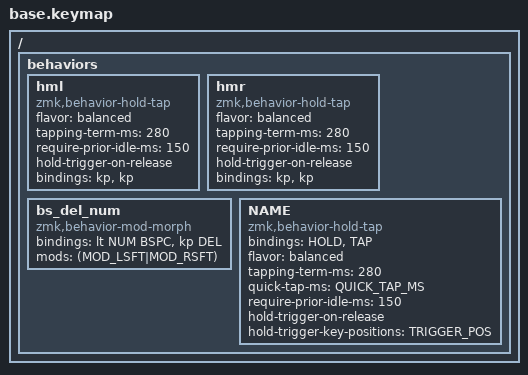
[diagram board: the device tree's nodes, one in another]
// https://github.com/urob/zmk-helpers/blob/main/docs/key_labels.md#examples
// clang-format off
#include <behaviors.dtsi>
#include <dt-bindings/zmk/keys.h>
#include "zmk-helpers/helper.h" // helper module
#include <dt-bindings/zmk/bt.h>
#include <dt-bindings/zmk/outputs.h>
#include "combos.dtsi"

/* Layer Definitions */
#define BASE 0
#define LOWER 1
#define RAISE 2
#define FUNCTION 3
#define ADJUST 4
#define GAMING 5
#define GAMING2 6
#define MOUSE 7

// alias
#define XXX &none
#define ___ &trans

/* Combos, leader key sequences, mouse emulation */

// #include "combos.dtsi" // Must be sourced after HRM-combo hack.

/* Behaviors */
// TODO adjust time, copy my qmk timing when we are ready to deploy this
// Timeless homerow mods - left
ZMK_HOLD_TAP(hml,
    flavor = "balanced";
    tapping-term-ms = <280>;
    require-prior-idle-ms = <150>;
    hold-trigger-on-release;
    bindings = <&kp>, <&kp>;
)
// right
ZMK_HOLD_TAP(hmr,
    flavor = "balanced";
    tapping-term-ms = <280>;
    require-prior-idle-ms = <150>;
    hold-trigger-on-release;
    bindings = <&kp>, <&kp>;
)

// Tap: backspace | Shift + tap: delete | Hold: num layer
ZMK_MOD_MORPH(bs_del_num,
    bindings = <&lt NUM BSPC>, <&kp DEL>;
    mods = <(MOD_LSFT|MOD_RSFT)>;
)

/* Homerow mods */

#define KEYS_L LT0 LT1 LT2 LT3 LT4 LM0 LM1 LM2 LM3 LM4 LB0 LB1 LB2 LB3 LB4
#define KEYS_R RT0 RT1 RT2 RT3 RT4 RM0 RM1 RM2 RM3 RM4 RB0 RB1 RB2 RB3 RB4
#ifndef LH2
  #define THUMBS LH1 LH0 RH0 RH1         // Thumbs on 34 keys.
#else
  #define THUMBS LH2 LH1 LH0 RH0 RH1 RH2 // Thumbs on 36+ keys.
#endif

#define MAKE_HRM(NAME, HOLD, TAP, TRIGGER_POS)                                 \
  ZMK_HOLD_TAP(NAME, bindings = <HOLD>, <TAP>; flavor = "balanced";            \
               tapping-term-ms = <280>; quick-tap-ms = <QUICK_TAP_MS>;         \
               require-prior-idle-ms = <150>; hold-trigger-on-release;         \
               hold-trigger-key-positions = <TRIGGER_POS>;)

MAKE_HRM(hml, &kp, &kp, KEYS_R THUMBS) // Left-hand HRMs.
MAKE_HRM(hmr, &kp, &kp, KEYS_L THUMBS) // Right-hand HRMs.

// Hack: Make HRM combos tap-only (cf, ZMK issue #544).
// urob feature we prob dont need
#define ZMK_COMBO_8(NAME, TAP, POS, LAYERS, COMBO_MS, IDLE_MS, HOLD, SIDE)     \
  MAKE_HRM(hm_combo_##NAME, &kp, TAP, SIDE THUMBS)                             \
  ZMK_COMBO_6(NAME, &hm_combo_##NAME HOLD 0, POS, LAYERS, COMBO_MS, IDLE_MS)

/* Combos, leader key sequences, mouse emulation */

// macros
   ZMK_MACRO(assign),
    // are these lines needed?!
    wait-ms = <30>;
    tap-ms = <30>;
            bindings = <&kp COLON &kp EQUAL>;
)
   ZMK_MACRO(arrow),
    wait-ms = <30>;
    tap-ms = <30>;
            bindings = <&kp MINUS &kp GT>;
)
   ZMK_MACRO(double_colon),
    wait-ms = <30>;
    tap-ms = <30>;
            bindings = <&kp COLON &kp COLON>;
)
   ZMK_MACRO(dotdot),
    wait-ms = <30>;
    tap-ms = <30>;
            bindings = <&kp DOT &kp DOT &kp FSLH>;
)
   ZMK_MACRO(range),
    wait-ms = <30>;
    tap-ms = <30>;
            bindings = <&kp DOT &kp DOT &kp EQUAL>;
)
   ZMK_MACRO(hmdr),
    wait-ms = <30>;
    tap-ms = <30>;
            bindings = <&kp TILDE &kp FSLH>;
)

// aliasing zmk_layer wrapper func to zmk_base_layer?
#ifndef ZMK_BASE_LAYER
  #define ZMK_BASE_LAYER(name, LT, RT, LM, RM, LB, RB, LH, RH)                 \
      ZMK_LAYER(name, LT RT LM RM LB RB LH RH)
#endif

/* The Master Layout */
// This macro uses the 8 blocks (Top/Middle/Bottom/Thumb for each hand)
// to define the layers regardless of the physical board.

        /* BASE
         * ┌─────┬─────┬─────┬─────┬─────┐       ┌─────┬─────┬─────┬─────┬─────┐
         * │Q/ESC│  W  │  E  │  R  │  T  │       │  Y  │  U  │  I  │  O  │  P  │
         * ├─────┼─────┼─────┼─────┼─────┤       ├─────┼─────┼─────┼─────┼─────┤
         * │GUI/A│ALT/S│CTL/D│SFT/F│  G  │       │  H  │SFT/J│CTL/K│ALT/L│GUI/;│
         * ├─────┼─────┼─────┼─────┼─────┤       ├─────┼─────┼─────┼─────┼─────┤
         * │  Z  │  X  │  C  │  V  │  B  │       │  N  │  M  │  ,  │  .  │  /  │
         * └─────┴─────┴─────┴─────┴─────┘       └─────┴─────┴─────┴─────┴─────┘
         * ┌─────┬─────┐       ┌─────┬─────┐
         * │SPC/R│BS/DE│       │ DEL │ENT/L│
         * └─────┴─────┘       └─────┴─────┘
         */
        ZMK_BASE_LAYER(base,
            // TODO where does this go now? display-name = "BASE";
                &td_q_esc    &kp W        &kp E         &kp R         &kp T,            &kp Y      &kp U         &kp I         &kp O        &kp P,
                &hml LGUI A &hml LALT S &hml LCTRL D &hml LSHFT F &kp G,            &kp H      &hmr RSHFT J &hmr RCTRL K &hmr RALT L &hmr RGUI SEMI,
                &kp Z        &kp X        &kp C         &kp V         &kp B,            &kp N      &kp M         &kp COMMA     &kp DOT      &kp FSLH,
                                                        &lt RAISE SPACE &bs_del,        &kp DEL    &lt LOWER RET
                  )

        /* LOWER - Numbers & Media
         * ┌─────┬─────┬─────┬─────┬─────┐       ┌─────┬─────┬─────┬─────┬─────┐
         * │  1  │  2  │  3  │  4  │  5  │       │  6  │  7  │  8  │  9  │  0  │
         * ├─────┼─────┼─────┼─────┼─────┤       ├─────┼─────┼─────┼─────┼─────┤
         * │     │     │ VOL+│ VOL-│ MUTE│       │  .  │  4  │  5  │  6  │  0  │
         * ├─────┼─────┼─────┼─────┼─────┤       ├─────┼─────┼─────┼─────┼─────┤
         * │     │     │PREV │PLAY │NEXT │       │     │  1  │  2  │  3  │     │
         * └─────┴─────┴─────┴─────┴─────┘       └─────┴─────┴─────┴─────┴─────┘
         * ┌─────┬─────┐       ┌─────┬─────┐
         * │     │ FN  │       │     │     │
         * └─────┴─────┘       └─────┴─────┘
         */
        ZMK_BASE_LAYER(lower,
            // display-name = "NUMPAD";
                &kp N1    &kp N2    &kp N3       &kp N4       &kp N5,            &kp N6    &kp N7  &kp N8  &kp N9  &kp N0,
                &trans    &trans    &kp C_VOL_UP &kp C_VOL_DN &kp C_MUTE,        &kp DOT   &kp N4  &kp N5  &kp N6  &kp N0,
                &trans    &trans    &kp C_PREV   &kp C_PP     &kp C_NEXT,        &trans    &kp N1  &kp N2  &kp N3  &trans,
                                                 &trans       &mo FUNCTION,      &trans    &trans
                  )

        /* RAISE - Symbols
         * ┌─────┬─────┬─────┬─────┬─────┐       ┌─────┬─────┬─────┬─────┬─────┐
         * │  \  │  $  │  |  │  -  │  [  │       │  ]  │  +  │  #  │  <  │  >  │
         * ├─────┼─────┼─────┼─────┼─────┤       ├─────┼─────┼─────┼─────┼─────┤
         * │  !  │  &  │  *  │  =  │  (  │       │  )  │  ^  │  _  │  "  │ ::  │
         * ├─────┼─────┼─────┼─────┼─────┤       ├─────┼─────┼─────┼─────┼─────┤
         * │  `  │  !  │ ->  │ :=  │  {  │       │  }  │  @  │  ,  │  .  │  /  │
         * └─────┴─────┴─────┴─────┴─────┘       └─────┴─────┴─────┴─────┴─────┘
         * ┌─────┬─────┐       ┌─────┬─────┐
         * │     │ ../ │       │ SPC │  ~  │
         * └─────┴─────┘       └─────┴─────┘
         */
        ZMK_BASE_LAYER(raise,
            // display-name = "SYMBOLS";
                &kp BSLH   &kp DLLR   &kp PIPE   &kp MINUS  &kp LBKT,          &kp RBKT   &kp PLUS   &kp HASH   &kp LESS_THAN    &kp GREATER_THAN,
                &kp EXCL   &kp AMPS   &kp STAR   &kp EQUAL  &kp LPAR,          &kp RPAR   &kp CARET  &kp UNDER  &kp DQT          &double_colon,
                &kp GRAVE  &kp EXCL   &arrow     &assign    &kp LBRC,          &kp RBRC   &kp AT     &kp COMMA  &kp DOT          &kp FSLH,
                                                 &trans     &dotdot,           &kp SPACE  &kp TILDE
                  )

        /* FUNCTION - Nav & F-Keys
         * ┌─────┬─────┬─────┬─────┬─────┐       ┌─────┬─────┬─────┬─────┬─────┐
         * │ F9  │ F10 │ F11 │ F12 │     │       │PGUP │ HOME│ END │ INS │     │
         * ├─────┼─────┼─────┼─────┼─────┤       ├─────┼─────┼─────┼─────┼─────┤
         * │ F5  │ F6  │ F7  │ F8  │     │       │ LEFT│ DOWN│  UP │RIGHT│     │
         * ├─────┼─────┼─────┼─────┼─────┤       ├─────┼─────┼─────┼─────┼─────┤
         * │ F1  │ F2  │ F3  │ F4  │     │       │PGDN │     │     │     │     │
         * └─────┴─────┴─────┴─────┴─────┘       └─────┴─────┴─────┴─────┴─────┘
         * ┌─────┬─────┐       ┌─────┬─────┐
         * │     │     │       │     │ DEL │
         * └─────┴─────┘       └─────┴─────┘
         */
        ZMK_BASE_LAYER(function,
            // display-name = "NAV";
                &kp F9     &kp F10    &kp F11    &kp F12    &trans,            &kp PG_UP  &kp HOME  &kp END   &kp INS   &trans,
                &kp F5     &kp F6     &kp F7     &kp F8     &trans,            &kp LEFT   &kp DOWN  &kp UP    &kp RIGHT  &trans,
                &kp F1     &kp F2     &kp F3     &kp F4     &trans,            &kp PG_DN  &trans    &trans    &trans     &trans,
                                                 &trans     &trans,            &trans     &kp DEL
                )

        /* ADJUST - System & Bluetooth
         * ┌─────┬─────┬─────┬─────┬─────┐       ┌─────┬─────┬─────┬─────┬─────┐
         * │BTCLR│ BT0 │ BT1 │ BT2 │ BT3 │       │     │     │     │     │GAME │
         * ├─────┼─────┼─────┼─────┼─────┤       ├─────┼─────┼─────┼─────┼─────┤
         * │     │     │     │     │     │       │     │     │     │     │     │
         * ├─────┼─────┼─────┼─────┼─────┤       ├─────┼─────┼─────┼─────┼─────┤
         * │RESET│ BOOT│     │     │     │       │     │     │     │ BOOT│RESET│
         * └─────┴─────┴─────┴─────┴─────┘       └─────┴─────┴─────┴─────┴─────┘
         * ┌─────┬─────┐       ┌─────┬─────┐
         * │     │     │       │     │     │
         * └─────┴─────┘       └─────┴─────┘
         */
        ZMK_BASE_LAYER(adjust,
            // display-name = "SYSTEM";
                &bt BT_CLR  &bt BT_SEL 0  &bt BT_SEL 1  &bt BT_SEL 2  &bt BT_SEL 3,      &trans  &trans  &trans  &trans      &tog GAMING,
                &trans      &trans        &trans        &trans        &trans,            &trans  &trans  &trans  &trans      &trans,
                &sys_reset  &bootloader   &trans        &trans        &trans,            &trans  &trans  &trans  &bootloader &sys_reset,
                                                        &trans        &trans,            &trans  &trans
                  )

        /* GAMING - No Mods
         * ┌─────┬─────┬─────┬─────┬─────┐       ┌─────┬─────┬─────┬─────┬─────┐
         * │  Q  │  W  │  E  │  R  │  T  │       │  Y  │  U  │  I  │  O  │  P  │
         * ├─────┼─────┼─────┼─────┼─────┤       ├─────┼─────┼─────┼─────┼─────┤
         * │  A  │  S  │  D  │  F  │  G  │       │  H  │  J  │  K  │  L  │  ;  │
         * ├─────┼─────┼─────┼─────┼─────┤       ├─────┼─────┼─────┼─────┼─────┤
         * │  Z  │  X  │  C  │  V  │  B  │       │  N  │  M  │  ,  │  .  │ BASE│
         * └─────┴─────┴─────┴─────┴─────┘       └─────┴─────┴─────┴─────┴─────┘
         * ┌─────┬─────┐       ┌─────┬─────┐
         * │ TAB │ SPC │       │ ENT │ BSPC│
         * └─────┴─────┘       └─────┴─────┘
         */
        ZMK_BASE_LAYER(gaming,
            // display-name = "GAMING";
                &kp Q     &kp W     &kp E     &kp R     &kp T,             &kp Y      &kp U     &kp I      &kp O     &kp P,
                &kp A     &kp S     &kp D     &kp F     &kp G,             &kp H      &kp J     &kp K      &kp L     &kp SEMI,
                &kp Z     &kp X     &kp C     &kp V     &kp B,             &kp N      &kp M     &kp COMMA  &kp DOT   &to BASE,
                                              &kp TAB   &kp SPACE,         &kp RET    &kp BSPC
                  )
